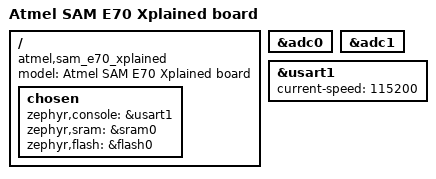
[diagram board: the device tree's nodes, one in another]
/*
 * Copyright (c) 2017 Piotr Mienkowski
 * Copyright (c) 2017 Justin Watson
 *
 * SPDX-License-Identifier: Apache-2.0
 */

/dts-v1/;

#include <atmel/same70.dtsi>

/ {
	model = "Atmel SAM E70 Xplained board";
	compatible = "atmel,sam_e70_xplained", "atmel,same70q21", "atmel,same70";

	chosen {
		zephyr,console = &usart1;
		zephyr,sram = &sram0;
		zephyr,flash = &flash0;
	};
};

&adc0 {
	status = "ok";
};

&adc1 {
	status = "ok";
};

&usart1 {
	current-speed = <115200>;
	status = "ok";
};
